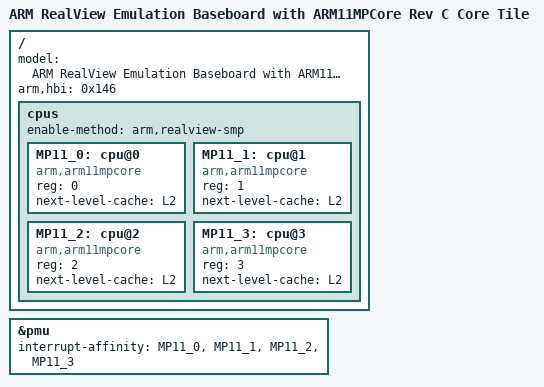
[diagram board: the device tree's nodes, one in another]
/dts-v1/;
#include "arm-realview-eb-mp.dtsi"
/ {
	model = "ARM RealView Emulation Baseboard with ARM11MPCore Rev C Core Tile";
	arm,hbi = <0x146>;
	cpus {
		#address-cells = <1>;
		#size-cells = <0>;
		enable-method = "arm,realview-smp";
		MP11_0: cpu@0 {
			device_type = "cpu";
			compatible = "arm,arm11mpcore";
			reg = <0>;
			next-level-cache = <&L2>;
		};
		MP11_1: cpu@1 {
			device_type = "cpu";
			compatible = "arm,arm11mpcore";
			reg = <1>;
			next-level-cache = <&L2>;
		};
		MP11_2: cpu@2 {
			device_type = "cpu";
			compatible = "arm,arm11mpcore";
			reg = <2>;
			next-level-cache = <&L2>;
		};
		MP11_3: cpu@3 {
			device_type = "cpu";
			compatible = "arm,arm11mpcore";
			reg = <3>;
			next-level-cache = <&L2>;
		};
	};
};
&pmu {
	interrupt-affinity = <&MP11_0>, <&MP11_1>, <&MP11_2>, <&MP11_3>;
};
